# STM32F7x7 register map
File version: 1.6
CPU: CM7 r0p0, little endian, no MPU, no FPU, 3 interrupt priority bits
Registers are 32-bit, read-write, reset 0x0 unless marked. A register's access mark holds for its fields unless they carry their own. Offsets are from the block's base; [hi:lo] are bit positions; {n}, {i} and the like mark numbered series; 'fields as' and 'values as' point back to an identical list.

## DMA2 — DMA controller
Base 0x40026400
Same registers: DMA1 0x40026000
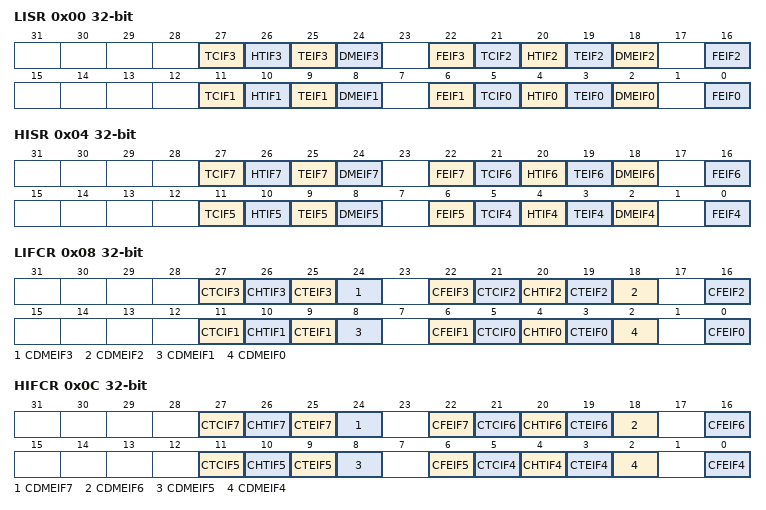
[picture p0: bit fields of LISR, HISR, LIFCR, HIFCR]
0x00 LISR ro — low interrupt status register
  [27] TCIF3 — Stream x transfer complete interrupt flag (x = 3..0)
  [26] HTIF3 — Stream x half transfer interrupt flag (x=3..0)
  [25] TEIF3 — Stream x transfer error interrupt flag (x=3..0)
  [24] DMEIF3 — Stream x direct mode error interrupt flag (x=3..0)
  [22] FEIF3 — Stream x FIFO error interrupt flag (x=3..0)
  [21] TCIF2 — Stream x transfer complete interrupt flag (x = 3..0)
  [20] HTIF2 — Stream x half transfer interrupt flag (x=3..0)
  [19] TEIF2 — Stream x transfer error interrupt flag (x=3..0)
  [18] DMEIF2 — Stream x direct mode error interrupt flag (x=3..0)
  [16] FEIF2 — Stream x FIFO error interrupt flag (x=3..0)
  [11] TCIF1 — Stream x transfer complete interrupt flag (x = 3..0)
  [10] HTIF1 — Stream x half transfer interrupt flag (x=3..0)
  [9] TEIF1 — Stream x transfer error interrupt flag (x=3..0)
  [8] DMEIF1 — Stream x direct mode error interrupt flag (x=3..0)
  [6] FEIF1 — Stream x FIFO error interrupt flag (x=3..0)
  [5] TCIF0 — Stream x transfer complete interrupt flag (x = 3..0)
  [4] HTIF0 — Stream x half transfer interrupt flag (x=3..0)
  [3] TEIF0 — Stream x transfer error interrupt flag (x=3..0)
  [2] DMEIF0 — Stream x direct mode error interrupt flag (x=3..0)
  [0] FEIF0 — Stream x FIFO error interrupt flag (x=3..0)
0x04 HISR ro — high interrupt status register
  [27] TCIF7 — Stream x transfer complete interrupt flag (x=7..4)
  [26] HTIF7 — Stream x half transfer interrupt flag (x=7..4)
  [25] TEIF7 — Stream x transfer error interrupt flag (x=7..4)
  [24] DMEIF7 — Stream x direct mode error interrupt flag (x=7..4)
  [22] FEIF7 — Stream x FIFO error interrupt flag (x=7..4)
  [21] TCIF6 — Stream x transfer complete interrupt flag (x=7..4)
  [20] HTIF6 — Stream x half transfer interrupt flag (x=7..4)
  [19] TEIF6 — Stream x transfer error interrupt flag (x=7..4)
  [18] DMEIF6 — Stream x direct mode error interrupt flag (x=7..4)
  [16] FEIF6 — Stream x FIFO error interrupt flag (x=7..4)
  [11] TCIF5 — Stream x transfer complete interrupt flag (x=7..4)
  [10] HTIF5 — Stream x half transfer interrupt flag (x=7..4)
  [9] TEIF5 — Stream x transfer error interrupt flag (x=7..4)
  [8] DMEIF5 — Stream x direct mode error interrupt flag (x=7..4)
  [6] FEIF5 — Stream x FIFO error interrupt flag (x=7..4)
  [5] TCIF4 — Stream x transfer complete interrupt flag (x=7..4)
  [4] HTIF4 — Stream x half transfer interrupt flag (x=7..4)
  [3] TEIF4 — Stream x transfer error interrupt flag (x=7..4)
  [2] DMEIF4 — Stream x direct mode error interrupt flag (x=7..4)
  [0] FEIF4 — Stream x FIFO error interrupt flag (x=7..4)
0x08 LIFCR — low interrupt flag clear register
  [27] CTCIF3 — Stream x clear transfer complete interrupt flag (x = 3..0)
  [26] CHTIF3 — Stream x clear half transfer interrupt flag (x = 3..0)
  [25] CTEIF3 — Stream x clear transfer error interrupt flag (x = 3..0)
  [24] CDMEIF3 — Stream x clear direct mode error interrupt flag (x = 3..0)
  [22] CFEIF3 — Stream x clear FIFO error interrupt flag (x = 3..0)
  [21] CTCIF2 — Stream x clear transfer complete interrupt flag (x = 3..0)
  [20] CHTIF2 — Stream x clear half transfer interrupt flag (x = 3..0)
  [19] CTEIF2 — Stream x clear transfer error interrupt flag (x = 3..0)
  [18] CDMEIF2 — Stream x clear direct mode error interrupt flag (x = 3..0)
  [16] CFEIF2 — Stream x clear FIFO error interrupt flag (x = 3..0)
  [11] CTCIF1 — Stream x clear transfer complete interrupt flag (x = 3..0)
  [10] CHTIF1 — Stream x clear half transfer interrupt flag (x = 3..0)
  [9] CTEIF1 — Stream x clear transfer error interrupt flag (x = 3..0)
  [8] CDMEIF1 — Stream x clear direct mode error interrupt flag (x = 3..0)
  [6] CFEIF1 — Stream x clear FIFO error interrupt flag (x = 3..0)
  [5] CTCIF0 — Stream x clear transfer complete interrupt flag (x = 3..0)
  [4] CHTIF0 — Stream x clear half transfer interrupt flag (x = 3..0)
  [3] CTEIF0 — Stream x clear transfer error interrupt flag (x = 3..0)
  [2] CDMEIF0 — Stream x clear direct mode error interrupt flag (x = 3..0)
  [0] CFEIF0 — Stream x clear FIFO error interrupt flag (x = 3..0)
0x0C HIFCR — high interrupt flag clear register
  [27] CTCIF7 — Stream x clear transfer complete interrupt flag (x = 7..4)
  [26] CHTIF7 — Stream x clear half transfer interrupt flag (x = 7..4)
  [25] CTEIF7 — Stream x clear transfer error interrupt flag (x = 7..4)
  [24] CDMEIF7 — Stream x clear direct mode error interrupt flag (x = 7..4)
  [22] CFEIF7 — Stream x clear FIFO error interrupt flag (x = 7..4)
  [21] CTCIF6 — Stream x clear transfer complete interrupt flag (x = 7..4)
  [20] CHTIF6 — Stream x clear half transfer interrupt flag (x = 7..4)
  [19] CTEIF6 — Stream x clear transfer error interrupt flag (x = 7..4)
  [18] CDMEIF6 — Stream x clear direct mode error interrupt flag (x = 7..4)
  [16] CFEIF6 — Stream x clear FIFO error interrupt flag (x = 7..4)
  [11] CTCIF5 — Stream x clear transfer complete interrupt flag (x = 7..4)
  [10] CHTIF5 — Stream x clear half transfer interrupt flag (x = 7..4)
  [9] CTEIF5 — Stream x clear transfer error interrupt flag (x = 7..4)
  [8] CDMEIF5 — Stream x clear direct mode error interrupt flag (x = 7..4)
  [6] CFEIF5 — Stream x clear FIFO error interrupt flag (x = 7..4)
  [5] CTCIF4 — Stream x clear transfer complete interrupt flag (x = 7..4)
  [4] CHTIF4 — Stream x clear half transfer interrupt flag (x = 7..4)
  [3] CTEIF4 — Stream x clear transfer error interrupt flag (x = 7..4)
  [2] CDMEIF4 — Stream x clear direct mode error interrupt flag (x = 7..4)
  [0] CFEIF4 — Stream x clear FIFO error interrupt flag (x = 7..4)
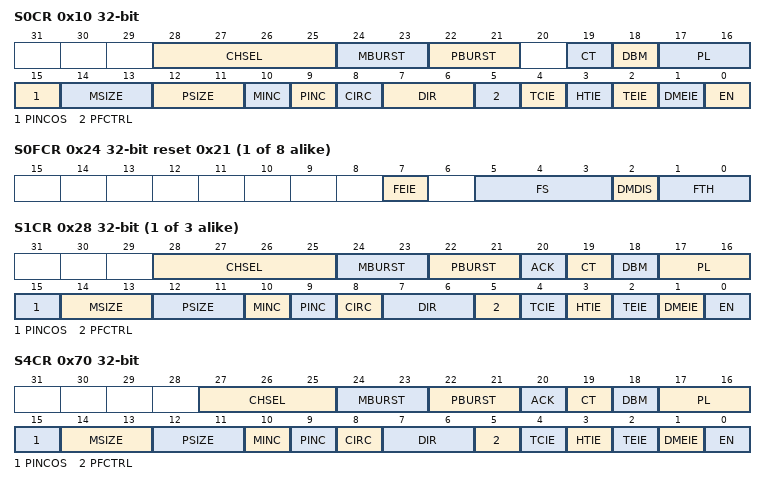
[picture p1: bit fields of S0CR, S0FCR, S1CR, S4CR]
0x10 S0CR — stream x configuration register
  [28:25] CHSEL — Channel selection
  [24:23] MBURST — Memory burst transfer configuration
  [22:21] PBURST — Peripheral burst transfer configuration
  [19] CT — Current target (only in double buffer mode)
  [18] DBM — Double buffer mode
  [17:16] PL — Priority level
  [15] PINCOS — Peripheral increment offset size
  [14:13] MSIZE — Memory data size
  [12:11] PSIZE — Peripheral data size
  [10] MINC — Memory increment mode
  [9] PINC — Peripheral increment mode
  [8] CIRC — Circular mode
  [7:6] DIR — Data transfer direction
  [5] PFCTRL — Peripheral flow controller
  [4] TCIE — Transfer complete interrupt enable
  [3] HTIE — Half transfer interrupt enable
  [2] TEIE — Transfer error interrupt enable
  [1] DMEIE — Direct mode error interrupt enable
  [0] EN — Stream enable / flag stream ready when read low
{0x14+0x18*i} S{i}NDTR (i=0..7) — stream x number of data register
  [15:0] NDT — Number of data items to transfer
{0x18+0x18*i} S{i}PAR (i=0..7) — stream x peripheral address register
  [31:0] PA — Peripheral address
{0x1C+0x18*i} S{i}M0AR (i=0..7) — stream x memory 0 address register
  [31:0] M0A — Memory 0 address
{0x20+0x18*i} S{i}M1AR (i=0..7) — stream x memory 1 address register
  [31:0] M1A — Memory 1 address (used in case of Double buffer mode)
{0x24+0x18*i} S{i}FCR access per field reset 0x21 (i=0..7) — stream x FIFO control register
  [7] FEIE rw — FIFO error interrupt enable
  [5:3] FS ro — FIFO status
  [2] DMDIS rw — Direct mode disable
  [1:0] FTH rw — FIFO threshold selection
{0x10+0x18*i} S{i}CR (i=1..3) — stream x configuration register
  [28:25] CHSEL — Channel selection
  [24:23] MBURST — Memory burst transfer configuration
  [22:21] PBURST — Peripheral burst transfer configuration
  [20] ACK
  [19] CT — Current target (only in double buffer mode)
  [18] DBM — Double buffer mode
  [17:16] PL — Priority level
  [15] PINCOS — Peripheral increment offset size
  [14:13] MSIZE — Memory data size
  [12:11] PSIZE — Peripheral data size
  [10] MINC — Memory increment mode
  [9] PINC — Peripheral increment mode
  [8] CIRC — Circular mode
  [7:6] DIR — Data transfer direction
  [5] PFCTRL — Peripheral flow controller
  [4] TCIE — Transfer complete interrupt enable
  [3] HTIE — Half transfer interrupt enable
  [2] TEIE — Transfer error interrupt enable
  [1] DMEIE — Direct mode error interrupt enable
  [0] EN — Stream enable / flag stream ready when read low
0x70 S4CR — stream x configuration register
  [27:25] CHSEL — Channel selection
  [24:23] MBURST — Memory burst transfer configuration
  [22:21] PBURST — Peripheral burst transfer configuration
  [20] ACK
  [19] CT — Current target (only in double buffer mode)
  [18] DBM — Double buffer mode
  [17:16] PL — Priority level
  [15] PINCOS — Peripheral increment offset size
  [14:13] MSIZE — Memory data size
  [12:11] PSIZE — Peripheral data size
  [10] MINC — Memory increment mode
  [9] PINC — Peripheral increment mode
  [8] CIRC — Circular mode
  [7:6] DIR — Data transfer direction
  [5] PFCTRL — Peripheral flow controller
  [4] TCIE — Transfer complete interrupt enable
  [3] HTIE — Half transfer interrupt enable
  [2] TEIE — Transfer error interrupt enable
  [1] DMEIE — Direct mode error interrupt enable
  [0] EN — Stream enable / flag stream ready when read low
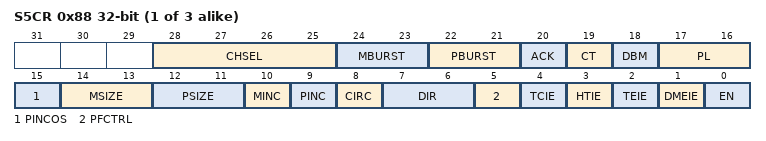
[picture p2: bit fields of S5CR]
{0x10+0x18*i} S{i}CR (i=5..7) — stream x configuration register
  fields as S1CR
